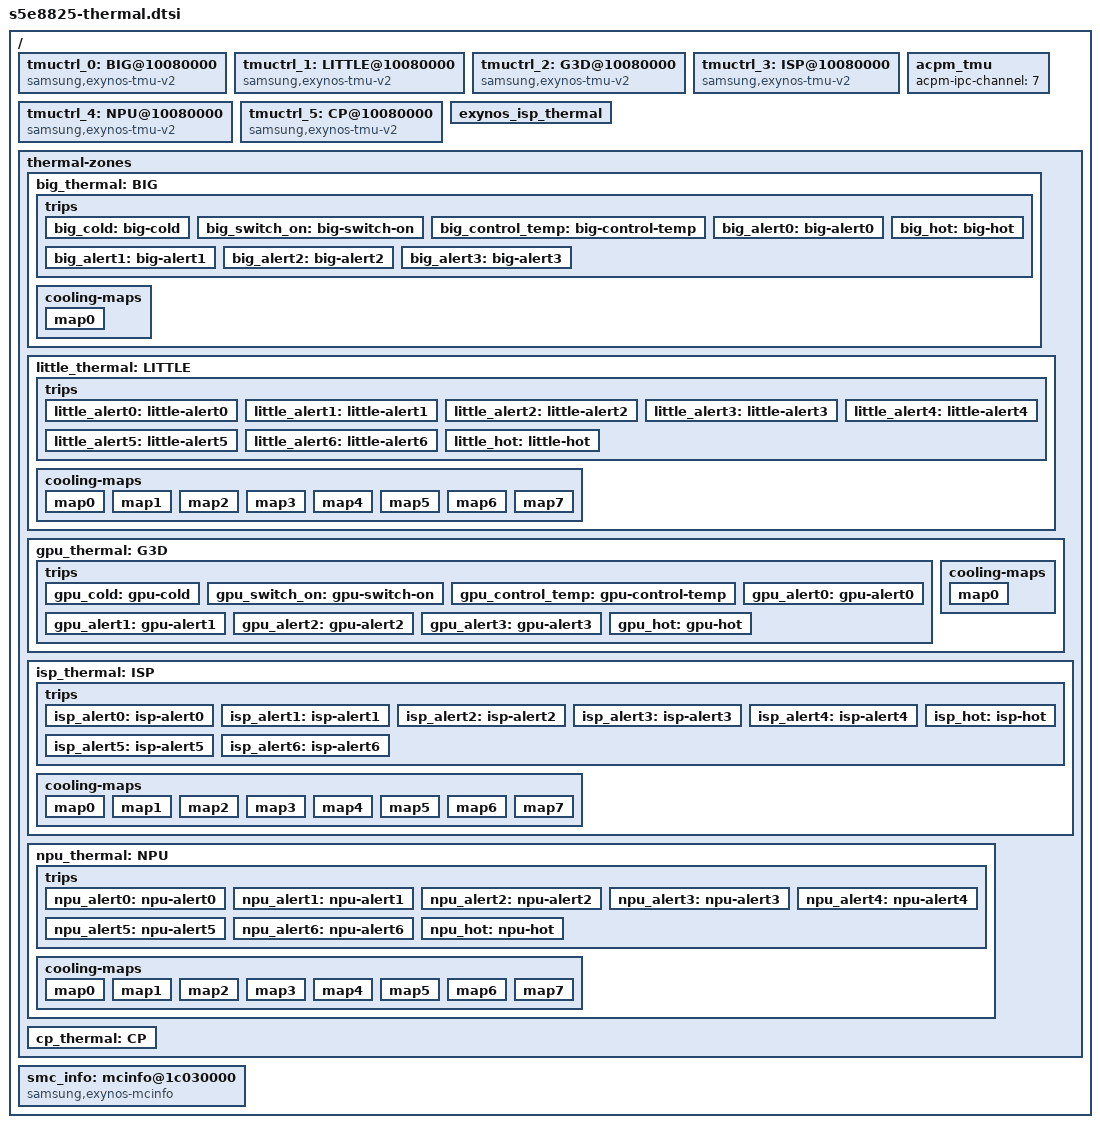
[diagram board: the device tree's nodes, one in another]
/*
 * SAMSUNG EXYNOS8825 SoC Dynamic Thermal Management device tree source
 *
 * Copyright (c) 2021 Samsung Electronics Co., Ltd.
 *		http://www.samsung.com
 *
 * SAMSUNG EXYNOS8825 SoC device nodes are listed in this file.
 * EXYNOS based board files can include this file and provide
 * values for board specfic bindings.
 *
 * This program is free software; you can redistribute it and/or modify
 * it under the terms of the GNU General Public License version 2 as
 * published by the Free Software Foundation.
 */

/ {
		tmuctrl_0: BIG@10080000 {
		compatible = "samsung,exynos-tmu-v2";
		reg = <0x0 0x10080000 0x800>;
		interrupts = <GIC_SPI INTREQ__TMU IRQ_TYPE_LEVEL_HIGH>;
		tmu_name = "BIG";
		id = <0>;
		hotplug_enable = <0>;
		hotplug_in_threshold = <91>;
		hotplug_out_threshold = <96>;
		cpu_domain = "6-7";
		#thermal-sensor-cells = <0>;
		cal_id = <ACPM_DVFS_CPUCL1>;

		use-pi-thermal;
		polling_delay_on = <20>;
		polling_delay_off = <1000>;
		k_po = <0>;
		k_pu = <0>;
		k_i = <0>;
		i_max = <0>;
		integral_cutoff = <0>;
		sustainable_power = <0>;

		emergency_frequency_v2;
	};

	tmuctrl_1: LITTLE@10080000 {
		compatible = "samsung,exynos-tmu-v2";
		reg = <0x0 0x10080000 0x800>;
		interrupts = <GIC_SPI INTREQ__TMU IRQ_TYPE_LEVEL_HIGH>;
		tmu_name = "LITTLE";
		id = <1>;
		#thermal-sensor-cells = <0>;
	};

	tmuctrl_2: G3D@10080000 {
		compatible = "samsung,exynos-tmu-v2";
		reg = <0x0 0x10080000 0x800>;
		interrupts = <GIC_SPI INTREQ__TMU IRQ_TYPE_LEVEL_HIGH>;
		tmu_name = "G3D";
		id = <2>;
		#thermal-sensor-cells = <0>;

		use-pi-thermal;
		polling_delay_on = <20>;
		polling_delay_off = <1000>;
		k_po = <0>;
		k_pu = <0>;
		k_i = <0>;
		i_max = <0>;
		integral_cutoff = <0>;
		sustainable_power = <0>;
	};

	tmuctrl_3: ISP@10080000 {
		compatible = "samsung,exynos-tmu-v2";
		reg = <0x0 0x10080000 0x800>;
		interrupts = <GIC_SPI INTREQ__TMU IRQ_TYPE_LEVEL_HIGH>;
		tmu_name = "ISP";
		id = <3>;
		#thermal-sensor-cells = <0>;
	};

	tmuctrl_4: NPU@10080000 {
		compatible = "samsung,exynos-tmu-v2";
		reg = <0x0 0x10080000 0x800>;
		interrupts = <GIC_SPI INTREQ__TMU IRQ_TYPE_LEVEL_HIGH>;
		tmu_name = "NPU";
		id = <4>;
		#thermal-sensor-cells = <0>;
	};

	tmuctrl_5: CP@10080000 {
		compatible = "samsung,exynos-tmu-v2";
		reg = <0x0 0x10080000 0x800>;
		interrupts = <GIC_SPI INTREQ__TMU IRQ_TYPE_LEVEL_HIGH>;
		tmu_name = "CP";
		id = <5>;
		#thermal-sensor-cells = <0>;
	};

	acpm_tmu {
		acpm-ipc-channel = <7>;
	};

	exynos_isp_thermal: exynos_isp_thermal {
		#cooling-cells = <2>; /* min followed by max */
	};

	thermal-zones {
		big_thermal: BIG {
			zone_name  = "BIG_THERMAL";
			polling-delay-passive = <0>;
			polling-delay = <0>;
			thermal-sensors = <&tmuctrl_0>;

			trips {
				big_cold: big-cold {
					temperature = <20000>;
					hysteresis = <5000>; /* millicelsius */
					type = "active";
				};
				big_switch_on: big-switch-on {
					temperature = <60000>; /* millicelsius */
					hysteresis = <2000>; /* millicelsius */
					type = "active";
				};
				big_control_temp: big-control-temp {
					temperature = <75000>; /* millicelsius */
					hysteresis = <5000>; /* millicelsius */
					type = "passive";
				};
				big_alert0: big-alert0 {
					temperature = <95000>; /* millicelsius */
					hysteresis = <5000>; /* millicelsius */
					type = "active";
				};
				big_alert1: big-alert1 {
					temperature = <100000>; /* millicelsius */
					hysteresis = <5000>; /* millicelsius */
					type = "active";
				};
				big_alert2: big-alert2 {
					temperature = <105000>; /* millicelsius */
					hysteresis = <5000>; /* millicelsius */
					type = "active";
				};
				big_alert3: big-alert3 {
					temperature = <110000>; /* millicelsius */
					hysteresis = <5000>; /* millicelsius */
					type = "active";
				};
				big_hot: big-hot {
					temperature = <120000>; /* millicelsius */
					hysteresis = <5000>; /* millicelsius */
					type = "hot";
				};
			};
			cooling-maps {
				map0 {
					trip = <&big_control_temp>;
					cooling-device = <&cpufreq_domain1 0 0>;
				};
			};
		};


		little_thermal: LITTLE {
			zone_name  = "LITTLE_THERMAL";
			polling-delay-passive = <0>;
			polling-delay = <0>;
			thermal-sensors = <&tmuctrl_1>;

			trips {
				little_alert0: little-alert0 {
					temperature = <20000>; /* millicelsius */
					hysteresis = <5000>; /* millicelsius */
					type = "active";
				};
				little_alert1: little-alert1 {
					temperature = <75000>; /* millicelsius */
					hysteresis = <5000>; /* millicelsius */
					type = "active";
				};
				little_alert2: little-alert2 {
					temperature = <80000>; /* millicelsius */
					hysteresis = <5000>; /* millicelsius */
					type = "active";
				};
				little_alert3: little-alert3 {
					temperature = <85000>; /* millicelsius */
					hysteresis = <5000>; /* millicelsius */
					type = "active";
				};
				little_alert4: little-alert4 {
					temperature = <90000>; /* millicelsius */
					hysteresis = <5000>; /* millicelsius */
					type = "active";
				};
				little_alert5: little-alert5 {
					temperature = <120000>; /* millicelsius */
					hysteresis = <5000>; /* millicelsius */
					type = "active";
				};
				little_alert6: little-alert6 {
					temperature = <120000>; /* millicelsius */
					hysteresis = <5000>; /* millicelsius */
					type = "active";
				};
				little_hot: little-hot {
					temperature = <120000>; /* millicelsius */
					hysteresis = <5000>; /* millicelsius */
					type = "hot";
				};
			};
			cooling-maps {
				map0 {
					trip = <&little_alert0>;
					cooling-device = <&cpufreq_domain0 0 0>;
				};
				map1 {
					trip = <&little_alert1>;
					cooling-device = <&cpufreq_domain0 0 0>;
				};
				map2 {
					trip = <&little_alert2>;
					cooling-device = <&cpufreq_domain0 0 0>;
				};
				map3 {
					trip = <&little_alert3>;
					cooling-device = <&cpufreq_domain0 0 0>;
				};
				map4 {
					trip = <&little_alert4>;
					cooling-device = <&cpufreq_domain0 0 0>;
				};
				map5 {
					trip = <&little_alert5>;
					cooling-device = <&cpufreq_domain0 0 0>;
				};
				map6 {
					trip = <&little_alert6>;
					cooling-device = <&cpufreq_domain0 0 0>;
				};
				map7 {
					trip = <&little_hot>;
					cooling-device = <&cpufreq_domain0 0 0>;
				};
			};
		};

		gpu_thermal: G3D {
			zone_name  = "G3D_THERMAL";
			polling-delay-passive = <0>;
			polling-delay = <0>;
			thermal-sensors = <&tmuctrl_2>;

			trips {
				gpu_cold: gpu-cold {
					temperature = <20000>;
					hysteresis = <5000>; /* millicelsius */
					type = "active";
				};
				gpu_switch_on: gpu-switch-on {
					temperature = <65000>; /* millicelsius */
					hysteresis = <2000>; /* millicelsius */
					type = "active";
				};
				gpu_control_temp: gpu-control-temp {
					temperature = <75000>; /* millicelsius */
					hysteresis = <5000>; /* millicelsius */
					type = "passive";
				};
				gpu_alert0: gpu-alert0 {
					temperature = <95000>; /* millicelsius */
					hysteresis = <5000>; /* millicelsius */
					type = "active";
				};
				gpu_alert1: gpu-alert1 {
					temperature = <100000>; /* millicelsius */
					hysteresis = <5000>; /* millicelsius */
					type = "active";
				};
				gpu_alert2: gpu-alert2 {
					temperature = <105000>; /* millicelsius */
					hysteresis = <5000>; /* millicelsius */
					type = "active";
				};
				gpu_alert3: gpu-alert3 {
					temperature = <110000>; /* millicelsius */
					hysteresis = <5000>; /* millicelsius */
					type = "active";
				};
				gpu_hot: gpu-hot {
					temperature = <120000>; /* millicelsius */
					hysteresis = <5000>; /* millicelsius */
					type = "hot";
				};
			};
			cooling-maps {
				map0 {
					trip = <&gpu_control_temp>;
					cooling-device = <&mali 0 0>;
				};
			};
		};

		isp_thermal: ISP {
			zone_name  = "ISP_THERMAL";
			polling-delay-passive = <0>;
			polling-delay = <0>;
			thermal-sensors = <&tmuctrl_3>;

			trips {
				isp_alert0: isp-alert0 {
					temperature = <20000>; /* millicelsius */
					hysteresis = <5000>; /* millicelsius */
					type = "active";
				};
				isp_alert1: isp-alert1 {
					temperature = <85000>; /* millicelsius */
					hysteresis = <5000>; /* millicelsius */
					type = "active";
				};
				isp_alert2: isp-alert2 {
					temperature = <950000>; /* millicelsius */
					hysteresis = <5000>; /* millicelsius */
					type = "active";
				};
				isp_alert3: isp-alert3 {
					temperature = <120000>; /* millicelsius */
					hysteresis = <5000>; /* millicelsius */
					type = "active";
				};
				isp_alert4: isp-alert4 {
					temperature = <120000>; /* millicelsius */
					hysteresis = <5000>; /* millicelsius */
					type = "active";
				};
				isp_alert5: isp-alert5 {
					temperature = <1200000>; /* millicelsius */
					hysteresis = <5000>; /* millicelsius */
					type = "active";
				};
				isp_alert6: isp-alert6 {
					temperature = <1200000>; /* millicelsius */
					hysteresis = <5000>; /* millicelsius */
					type = "active";
				};
				isp_hot: isp-hot {
					temperature = <120000>; /* millicelsius */
					hysteresis = <5000>; /* millicelsius */
					type = "hot";
				};
			};

			cooling-maps {
				map0 {
					trip = <&isp_alert0>;
					cooling-device = <&exynos_isp_thermal 0 0>;
				};
				map1 {
					trip = <&isp_alert1>;
					cooling-device = <&exynos_isp_thermal 0 0>;
				};
				map2 {
					trip = <&isp_alert2>;
					cooling-device = <&exynos_isp_thermal 0 0>;
				};
				map3 {
					trip = <&isp_alert3>;
					cooling-device = <&exynos_isp_thermal 0 0>;
				};
				map4 {
					trip = <&isp_alert4>;
					cooling-device = <&exynos_isp_thermal 0 0>;
				};
				map5 {
					trip = <&isp_alert5>;
					cooling-device = <&exynos_isp_thermal 0 0>;
				};
				map6 {
					trip = <&isp_alert6>;
					cooling-device = <&exynos_isp_thermal 0 0>;
				};
				map7 {
					trip = <&isp_hot>;
					cooling-device = <&exynos_isp_thermal 0 0>;
				};
			};
		};

		npu_thermal: NPU {
			zone_name  = "NPU_THERMAL";
			polling-delay-passive = <0>;
			polling-delay = <0>;
			thermal-sensors = <&tmuctrl_4>;

			trips {
				npu_alert0: npu-alert0 {
					temperature = <20000>; /* millicelsius */
					hysteresis = <5000>; /* millicelsius */
					type = "active";
				};
				npu_alert1: npu-alert1 {
					temperature = <85000>; /* millicelsius */
					hysteresis = <5000>; /* millicelsius */
					type = "active";
				};
				npu_alert2: npu-alert2 {
					temperature = <90000>; /* millicelsius */
					hysteresis = <5000>; /* millicelsius */
					type = "active";
				};
				npu_alert3: npu-alert3 {
					temperature = <120000>; /* millicelsius */
					hysteresis = <5000>; /* millicelsius */
					type = "active";
				};
				npu_alert4: npu-alert4 {
					temperature = <120000>; /* millicelsius */
					hysteresis = <5000>; /* millicelsius */
					type = "active";
				};
				npu_alert5: npu-alert5 {
					temperature = <120000>; /* millicelsius */
					hysteresis = <5000>; /* millicelsius */
					type = "active";
				};
				npu_alert6: npu-alert6 {
					temperature = <120000>; /* millicelsius */
					hysteresis = <5000>; /* millicelsius */
					type = "active";
				};
				npu_hot: npu-hot {
					temperature = <120000>; /* millicelsius */
					hysteresis = <5000>; /* millicelsius */
					type = "hot";
				};
			};

			cooling-maps {
				map0 {
					trip = <&npu_alert0>;
					cooling-device = <&devfreq_2 0 0>;
				};
				map1 {
					trip = <&npu_alert1>;
					cooling-device = <&devfreq_2 0 0>;
				};
				map2 {
					trip = <&npu_alert2>;
					cooling-device = <&devfreq_2 0 0>;
				};
				map3 {
					trip = <&npu_alert3>;
					cooling-device = <&devfreq_2 0 0>;
				};
				map4 {
					trip = <&npu_alert4>;
					cooling-device = <&devfreq_2 0 0>;
				};
				map5 {
					trip = <&npu_alert5>;
					cooling-device = <&devfreq_2 0 0>;
				};
				map6 {
					trip = <&npu_alert6>;
					cooling-device = <&devfreq_2 0 0>;
				};
				map7 {
					trip = <&npu_hot>;
					cooling-device = <&devfreq_2 0 0>;
				};
			};
		};
		cp_thermal: CP {
			zone_name = "CP_THERMAL";
			polling-delay-passive = <0>;
			polling-delay = <0>;
			thermal-sensors = <&tmuctrl_5>;
		};
	};
	smc_info: mcinfo@1c030000 {
			compatible = "samsung,exynos-mcinfo";
			reg = <0x0 0x104500f4 0x4>,
			      <0x0 0x105500f4 0x4>;
			bit_field = <0 4>;
			/* start bit, width */
			basecnt = <2>;
			irqcnt = <2>;

			reset_cond = <0x7>;

			interrupts = <GIC_SPI INTREQ__TEMPERR_INTR_MIF0 IRQ_TYPE_LEVEL_HIGH>,
				     <GIC_SPI INTREQ__TEMPERR_INTR_MIF1 IRQ_TYPE_LEVEL_HIGH>;
	};

#if 0
	amb_control {
		compatible = "samsung,exynos-amb-control";
		amb_tz_name = "battery";

		default_sampling_rate = <1000>;
		high_sampling_rate = <100>;
		increase_sampling_temp = <55000>;
		decrease_sampling_temp = <50000>;

		mcinfo_threshold = <60000>;

		tz_big {
			tz = <&big_thermal>;

			hotplug_cpu_list = "7";
			hotplug_in_threshold = <60000>;
			hotplug_out_threshold = <65000>;

			trip_set {
				trip_0 {
					trigger_cond = <1>;
					trip_point = <2>;
					trigger_temp = <60000>;
					release_temp = <55000>;
					throttle_temp = <75000>;
				};
			};
		};

		tz_mid {
			tz = <&mid_thermal>;

			hotplug_cpu_list = "4-6";
			hotplug_in_threshold = <60000>;
			hotplug_out_threshold = <65000>;

			trip_set {
				trip_0 {
					trigger_cond = <1>;
					trip_point = <2>;
					trigger_temp = <60000>;
					release_temp = <55000>;
					throttle_temp = <75000>;
				};
			};
		};

		tz_lit {
			tz = <&little_thermal>;

			hotplug_cpu_list = "2-3";
			hotplug_in_threshold = <70000>;
			hotplug_out_threshold = <75000>;
		};

		tz_isp {
			tz = <&isp_thermal>;

			trip_set {
				trip_0 {
					trigger_cond = <0>;
					trip_point = <1>;
					trigger_temp = <60000>;
					release_temp = <55000>;
					throttle_temp = <95000>;
				};
			};
		};
	};
#endif
};

